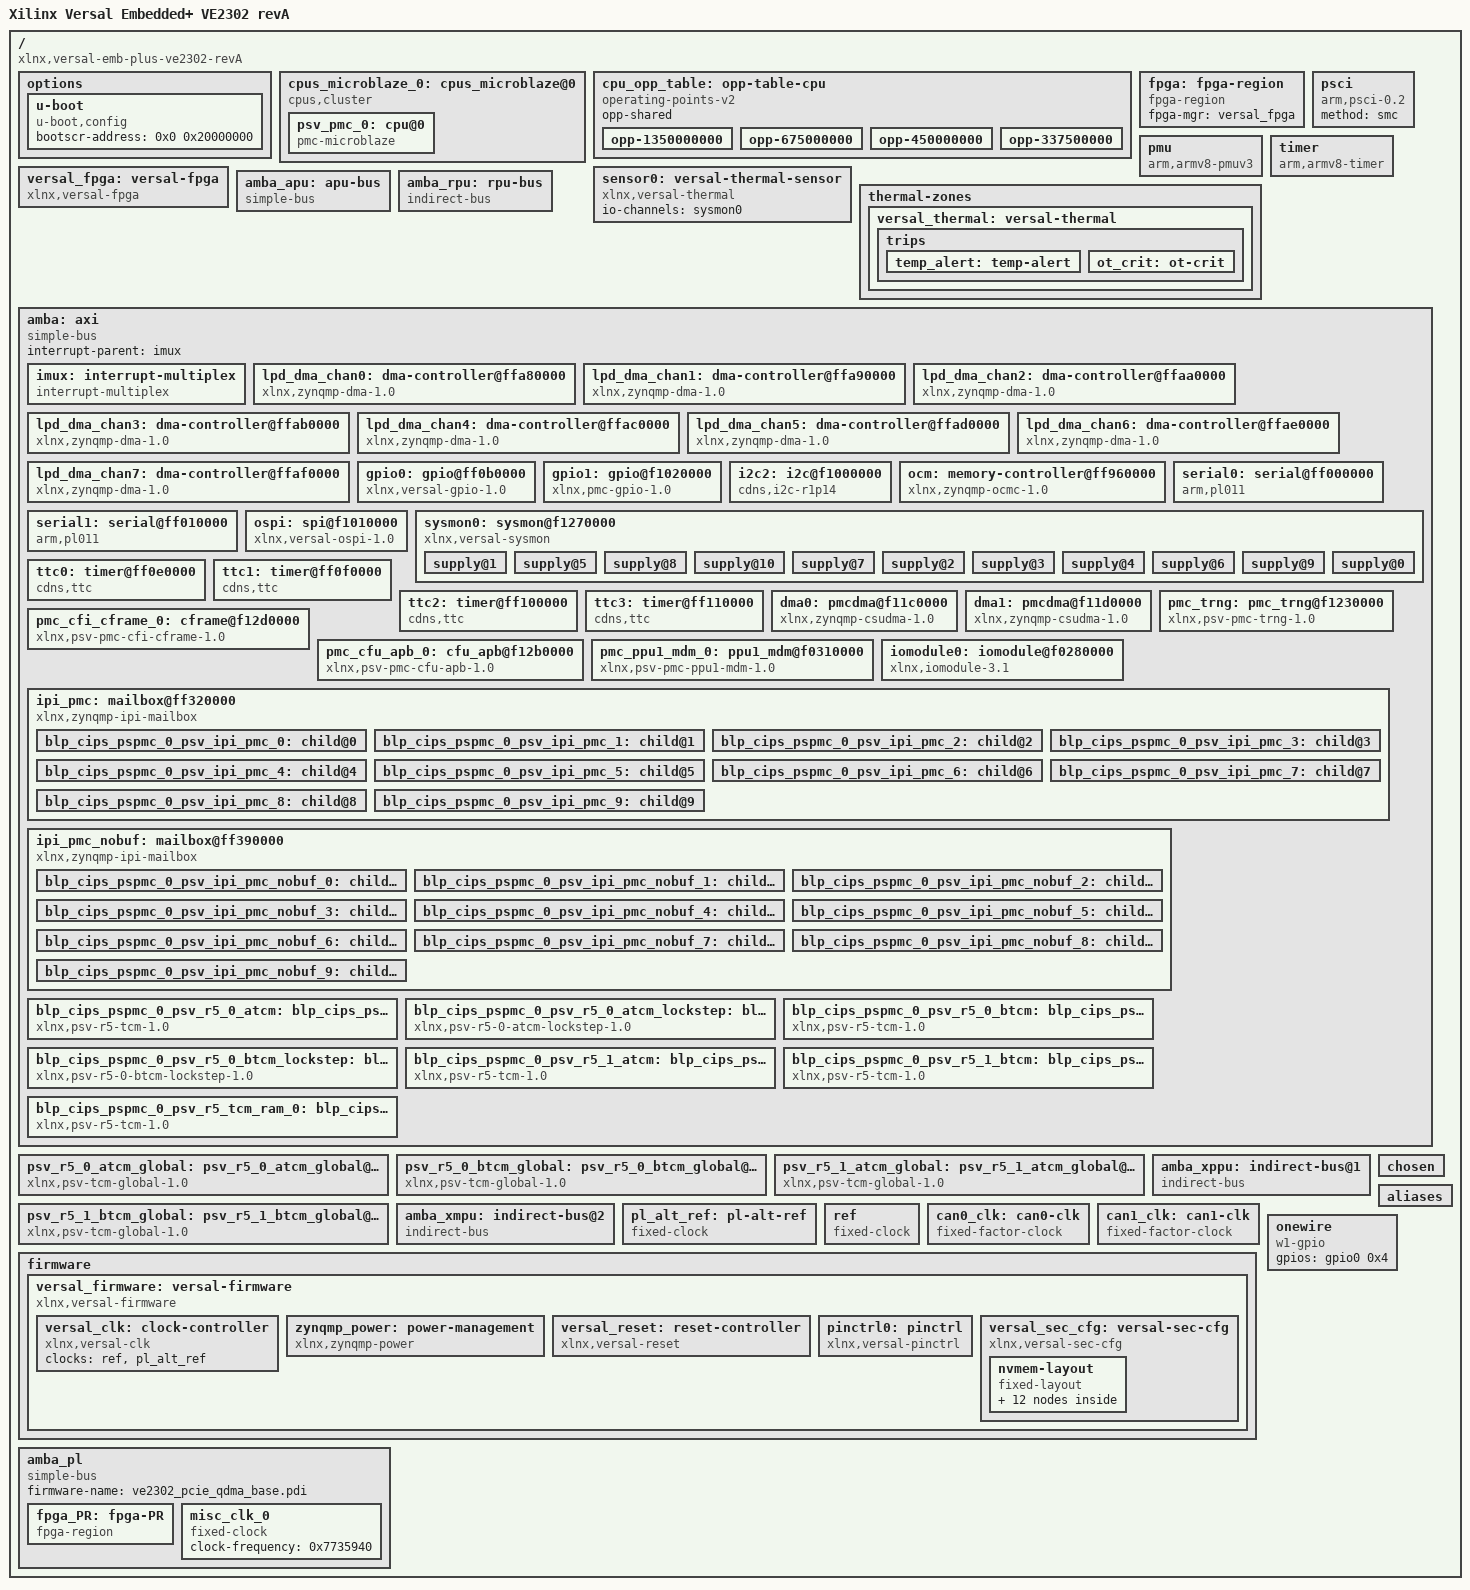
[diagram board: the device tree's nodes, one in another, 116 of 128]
/dts-v1/;
/ {
        compatible = "xlnx,versal-emb-plus-ve2302-revA", "xlnx,versal-emb-plus-ve2302", "xlnx,versal";
        #address-cells = <0x2>;
        #size-cells = <0x2>;
        model = "Xilinx Versal Embedded+ VE2302 revA";
        board = "emb-plus-vpr-4616";
        device_id = "xcve2302";
        slrcount = <0x1>;
        family = "Versal";
        speed_grade = "2MP";
        pruned-sdt = <0x1>;

        options {

                u-boot {
                        compatible = "u-boot,config";
                        bootscr-address = <0x0 0x20000000>;
                };
        };

        cpus_microblaze_0: cpus_microblaze@0 {
                #address-cells = <0x1>;
                #size-cells = <0x0>;
                compatible = "cpus,cluster";
                address-map = <0xf0000000 &amba 0xf0000000 0x10000000>,
                 <0xff320000 &ipi_pmc 0xff320000 0x10000>,
                 <0xff390000 &ipi_pmc_nobuf 0xff390000 0x10000>,
                 <0xf0310000 &pmc_ppu1_mdm_0 0xf0310000 0x8000>,
                 <0xf1000000 &i2c2 0xf1000000 0x10000>,
                 <0xf1010000 &ospi 0xf1010000 0x10000>,
                 <0xf1020000 &gpio1 0xf1020000 0x10000>,
                 <0xf11c0000 &dma0 0xf11c0000 0x10000>,
                 <0xf11d0000 &dma1 0xf11d0000 0x10000>,
                 <0xf1230000 &pmc_trng 0xf1230000 0x10000>,
                 <0xf1270000 &sysmon0 0xf1270000 0x30000>,
                 <0xf12b0000 &pmc_cfu_apb_0 0xf12b0000 0x10000>,
                 <0xf12d0000 &pmc_cfi_cframe_0 0xf12d0000 0x1000>,
                 <0xff000000 &serial0 0xff000000 0x10000>,
                 <0xff010000 &serial1 0xff010000 0x10000>,
                 <0xff0b0000 &gpio0 0xff0b0000 0x10000>,
                 <0xff0e0000 &ttc0 0xff0e0000 0x10000>,
                 <0xff0f0000 &ttc1 0xff0f0000 0x10000>,
                 <0xff100000 &ttc2 0xff100000 0x10000>,
                 <0xff110000 &ttc3 0xff110000 0x10000>,
                 <0xffa80000 &lpd_dma_chan0 0xffa80000 0x10000>,
                 <0xffa90000 &lpd_dma_chan1 0xffa90000 0x10000>,
                 <0xffaa0000 &lpd_dma_chan2 0xffaa0000 0x10000>,
                 <0xffab0000 &lpd_dma_chan3 0xffab0000 0x10000>,
                 <0xffac0000 &lpd_dma_chan4 0xffac0000 0x10000>,
                 <0xffad0000 &lpd_dma_chan5 0xffad0000 0x10000>,
                 <0xffae0000 &lpd_dma_chan6 0xffae0000 0x10000>,
                 <0xffaf0000 &lpd_dma_chan7 0xffaf0000 0x10000>,
                 <0xf0280000 &iomodule0 0xf0280000 0x1000>;
                #ranges-address-cells = <0x1>;
                #ranges-size-cells = <0x1>;
                phandle = <0xb6>;

                psv_pmc_0: cpu@0 {
                        compatible = "pmc-microblaze";
                        device_type = "cpu";
                        reg = <0x0>;
                        operating-points-v2 = <&cpu_opp_table>;
                        xlnx,d-axi = <0x1>;
                        xlnx,addr-tag-bits = <0x0>;
                        xlnx,m-axi-dc-thread-id-width = <0x1>;
                        xlnx,m0-axis-protocol = "GENERIC";
                        xlnx,dcache-force-tag-lutram = <0x0>;
                        xlnx,interrupt-is-edge = <0x0>;
                        xlnx,use-mmu = <0x0>;
                        xlnx,m-axi-dp-exclusive-access = <0x0>;
                        xlnx,use-reorder-instr = <0x1>;
                        xlnx,m14-axis-protocol = "GENERIC";
                        xlnx,use-div = <0x1>;
                        xlnx,dc-axi-mon = <0x0>;
                        xlnx,m-axi-ic-user-signals = <0x0>;
                        xlnx,use-config-reset = <0x0>;
                        xlnx,s14-axis-protocol = "GENERIC";
                        xlnx,mmu-zones = <0x10>;
                        xlnx,enable-discrete-ports = <0x0>;
                        xlnx,d-lmb = <0x1>;
                        xlnx,m-axi-dc-exclusive-access = <0x0>;
                        xlnx,debug-interface = <0x0>;
                        xlnx,s9-axis-protocol = "GENERIC";
                        xlnx,sco = <0x0>;
                        xlnx,use-ext-brk = <0x0>;
                        xlnx,debug-enabled = <0x1>;
                        xlnx,daddr-size = <0x20>;
                        xlnx,s0-axis-data-width = <0x20>;
                        xlnx,use-extended-fsl-instr = <0x0>;
                        xlnx,m-axi-dc-user-signals = <0x0>;
                        xlnx,reset-msr = <0x0>;
                        xlnx,branch-target-cache-size = <0x0>;
                        xlnx,s2-axis-data-width = <0x20>;
                        xlnx,cache-byte-size = <0x2000>;
                        bus-handle = <0x1>;
                        xlnx,mmu-tlb-access = <0x3>;
                        xlnx,s4-axis-data-width = <0x20>;
                        xlnx,m-axi-ic-awuser-width = <0x5>;
                        xlnx,s6-axis-data-width = <0x20>;
                        xlnx,s4-axis-protocol = "GENERIC";
                        xlnx,s8-axis-data-width = <0x20>;
                        xlnx,edk-special = "microblaze";
                        xlnx,use-dcache = <0x0>;
                        xlnx,m-axi-dp-addr-width = <0x20>;
                        xlnx,m-axi-ic-wuser-width = <0x1>;
                        xlnx,i-axi = <0x0>;
                        xlnx,icache-streams = <0x0>;
                        xlnx,m-axi-dc-awuser-width = <0x5>;
                        xlnx,pss-ref-clk-freq = <0x1fca034>;
                        xlnx,use-stack-protection = <0x1>;
                        xlnx,m6-axis-protocol = "GENERIC";
                        xlnx,num-sync-ff-dbg-clk = <0x1>;
                        xlnx,m-axi-ip-data-width = <0x20>;
                        d-cache-size = <0x2000>;
                        xlnx,use-pcmp-instr = <0x1>;
                        xlnx,area-optimized = <0x0>;
                        xlnx,avoid-primitives = <0x0>;
                        xlnx,m1-axis-protocol = "GENERIC";
                        xlnx,i-lmb = <0x1>;
                        xlnx,lockstep-select = <0x0>;
                        xlnx,dcache-data-width = <0x0>;
                        xlnx,icache-force-tag-lutram = <0x0>;
                        xlnx,m15-axis-protocol = "GENERIC";
                        xlnx,use-branch-target-cache = <0x0>;
                        xlnx,m-axi-ip-thread-id-width = <0x1>;
                        xlnx,mmu-itlb-size = <0x2>;
                        xlnx,number-of-pc-brk = <0x2>;
                        xlnx,imprecise-exceptions = <0x0>;
                        xlnx,m-axi-ic-buser-width = <0x1>;
                        xlnx,m-axi-ic-addr-width = <0x20>;
                        xlnx,s15-axis-protocol = "GENERIC";
                        d-cache-highaddr = <0x3fffffff>;
                        xlnx,m10-axis-protocol = "GENERIC";
                        xlnx,optimization = <0x0>;
                        xlnx,m-axi-ic-aruser-width = <0x5>;
                        xlnx,d-lmb-mon = <0x0>;
                        xlnx,s10-axis-protocol = "GENERIC";
                        xlnx,m-axi-ic-ruser-width = <0x1>;
                        xlnx,s5-axis-protocol = "GENERIC";
                        xlnx,fault-tolerant = <0x1>;
                        d-cache-line-size = <0x10>;
                        xlnx,m-axi-dc-aruser-width = <0x5>;
                        xlnx,mmu-privileged-instr = <0x0>;
                        xlnx,m-axi-i-bus-exception = <0x0>;
                        xlnx,reset-msr-eip = <0x0>;
                        xlnx,endianness = <0x1>;
                        xlnx,reset-msr-ice = <0x0>;
                        xlnx,dp-axi-mon = <0x0>;
                        xlnx,s10-axis-data-width = <0x20>;
                        xlnx,s0-axis-protocol = "GENERIC";
                        xlnx,s12-axis-data-width = <0x20>;
                        xlnx,m7-axis-protocol = "GENERIC";
                        xlnx,s14-axis-data-width = <0x20>;
                        xlnx,m-axi-d-bus-exception = <0x1>;
                        xlnx,reset-msr-bip = <0x1>;
                        xlnx,debug-external-trace = <0x0>;
                        xlnx,addr-size = <0x20>;
                        xlnx,m-axi-ic-user-value = <0x1f>;
                        xlnx,m1-axis-data-width = <0x20>;
                        xlnx,debug-event-counters = <0x5>;
                        xlnx,m3-axis-data-width = <0x20>;
                        xlnx,fpu-exception = <0x0>;
                        xlnx,m2-axis-protocol = "GENERIC";
                        xlnx,m5-axis-data-width = <0x20>;
                        xlnx,m7-axis-data-width = <0x20>;
                        xlnx,edk-iptype = "PROCESSOR";
                        xlnx,debug-latency-counters = <0x1>;
                        xlnx,interconnect = <0x2>;
                        xlnx,m9-axis-data-width = <0x20>;
                        xlnx,edge-is-positive = <0x1>;
                        xlnx,use-icache = <0x0>;
                        xlnx,async-wakeup = <0x3>;
                        xlnx,m10-axis-data-width = <0x20>;
                        xlnx,m12-axis-data-width = <0x20>;
                        xlnx,use-ext-nm-brk = <0x0>;
                        xlnx,m11-axis-protocol = "GENERIC";
                        xlnx,m14-axis-data-width = <0x20>;
                        xlnx,icache-always-used = <0x0>;
                        xlnx,ic-axi-mon = <0x0>;
                        xlnx,num-sync-ff-clk-irq = <0x1>;
                        xlnx,freq = <0x1312d000>;
                        xlnx,lockstep-master = <0x0>;
                        xlnx,s11-axis-protocol = "GENERIC";
                        xlnx,use-msr-instr = <0x1>;
                        xlnx,s6-axis-protocol = "GENERIC";
                        xlnx,iaddr-size = <0x20>;
                        xlnx,interrupt-mon = <0x0>;
                        xlnx,m-axi-dc-data-width = <0x20>;
                        xlnx,dynamic-bus-sizing = <0x0>;
                        xlnx,number-of-wr-addr-brk = <0x1>;
                        xlnx,use-interrupt = <0x1>;
                        xlnx,m-axi-ip-addr-width = <0x20>;
                        xlnx,async-interrupt = <0x1>;
                        xlnx,pc-width = <0x20>;
                        xlnx,icache-victims = <0x0>;
                        xlnx,reset-msr-ee = <0x0>;
                        xlnx,s1-axis-protocol = "GENERIC";
                        xlnx,m8-axis-protocol = "GENERIC";
                        i-cache-baseaddr = <0x0>;
                        xlnx,i-lmb-mon = <0x0>;
                        xlnx,dcache-byte-size = <0x2000>;
                        xlnx,m-axi-dp-thread-id-width = <0x1>;
                        xlnx,data-size = <0x20>;
                        xlnx,m-axi-dc-wuser-width = <0x1>;
                        xlnx,fsl-exception = <0x0>;
                        xlnx,m3-axis-protocol = "GENERIC";
                        xlnx,s1-axis-data-width = <0x20>;
                        xlnx,dcache-use-writeback = <0x0>;
                        xlnx,div-zero-exception = <0x1>;
                        xlnx,s3-axis-data-width = <0x20>;
                        xlnx,base-vectors = <0xf0240000>;
                        xlnx,icache-line-len = <0x4>;
                        xlnx,s5-axis-data-width = <0x20>;
                        xlnx,s7-axis-data-width = <0x20>;
                        xlnx,allow-dcache-wr = <0x1>;
                        xlnx,s9-axis-data-width = <0x20>;
                        xlnx,use-barrel = <0x1>;
                        xlnx,g-use-exceptions = <0x1>;
                        xlnx,dcache-line-len = <0x4>;
                        xlnx,m12-axis-protocol = "GENERIC";
                        xlnx,num-sync-ff-clk = <0x2>;
                        i-cache-size = <0x2000>;
                        xlnx,instance = "design_1_microblaze_0_0";
                        xlnx,reset-msr-ie = <0x0>;
                        xlnx,s12-axis-protocol = "GENERIC";
                        xlnx,dcache-addr-tag = <0x0>;
                        xlnx,m-axi-ic-thread-id-width = <0x1>;
                        xlnx,number-of-rd-addr-brk = <0x1>;
                        xlnx,m-axi-dc-buser-width = <0x1>;
                        xlnx,s7-axis-protocol = "GENERIC";
                        xlnx,lockstep-slave = <0x0>;
                        xlnx,debug-profile-size = <0x0>;
                        xlnx,s2-axis-protocol = "GENERIC";
                        xlnx,m9-axis-protocol = "GENERIC";
                        xlnx,debug-counter-width = <0x20>;
                        xlnx,icache-data-width = <0x0>;
                        xlnx,m-axi-dc-ruser-width = <0x1>;
                        xlnx,reset-msr-dce = <0x0>;
                        xlnx,ip-name = "psv_pmc";
                        xlnx,ip-axi-mon = <0x0>;
                        xlnx,m-axi-dp-data-width = <0x20>;
                        xlnx,m4-axis-protocol = "GENERIC";
                        xlnx,dcache-always-used = <0x0>;
                        xlnx,ill-opcode-exception = <0x1>;
                        xlnx,trace = <0x1>;
                        xlnx,pvr = <0x2>;
                        xlnx,debug-trace-size = <0x2000>;
                        i-cache-line-size = <0x10>;
                        xlnx,m13-axis-protocol = "GENERIC";
                        xlnx,s11-axis-data-width = <0x20>;
                        xlnx,m-axi-dc-addr-width = <0x20>;
                        xlnx,s13-axis-data-width = <0x20>;
                        xlnx,ecc-use-ce-exception = <0x0>;
                        xlnx,opcode-0x0-illegal = <0x1>;
                        xlnx,pvr-user2 = <0x0>;
                        xlnx,s15-axis-data-width = <0x20>;
                        xlnx,s13-axis-protocol = "GENERIC";
                        xlnx,m0-axis-data-width = <0x20>;
                        i-cache-highaddr = <0x3fffffff>;
                        xlnx,s8-axis-protocol = "GENERIC";
                        xlnx,m2-axis-data-width = <0x20>;
                        xlnx,num-sync-ff-clk-debug = <0x2>;
                        xlnx,allow-icache-wr = <0x1>;
                        xlnx,m4-axis-data-width = <0x20>;
                        xlnx,g-template-list = <0x0>;
                        xlnx,m6-axis-data-width = <0x20>;
                        xlnx,m-axi-ic-data-width = <0x20>;
                        xlnx,m8-axis-data-width = <0x20>;
                        xlnx,use-hw-mul = <0x2>;
                        xlnx,use-fpu = <0x0>;
                        xlnx,s3-axis-protocol = "GENERIC";
                        xlnx,use-non-secure = <0x0>;
                        d-cache-baseaddr = <0x0>;
                        xlnx,m11-axis-data-width = <0x20>;
                        xlnx,m13-axis-data-width = <0x20>;
                        xlnx,instr-size = <0x20>;
                        xlnx,m15-axis-data-width = <0x20>;
                        xlnx,mmu-dtlb-size = <0x4>;
                        xlnx,fsl-links = <0x0>;
                        xlnx,m5-axis-protocol = "GENERIC";
                        xlnx,dcache-victims = <0x0>;
                        xlnx,m-axi-dc-user-value = <0x1f>;
                        xlnx,unaligned-exceptions = <0x1>;
                        phandle = <0xb7>;
                };
        };

        cpu_opp_table: opp-table-cpu {
                compatible = "operating-points-v2";
                opp-shared;
                phandle = <0x8c>;

                opp-1350000000 {
                        opp-hz = <0x0 0x50775d80>;
                        clock-latency-ns = <0x7a120>;
                        opp-microvolt = <0xf4240>;
                };

                opp-675000000 {
                        opp-hz = <0x0 0x283baec0>;
                        clock-latency-ns = <0x7a120>;
                        opp-microvolt = <0xf4240>;
                };

                opp-450000000 {
                        opp-hz = <0x0 0x1ad27480>;
                        clock-latency-ns = <0x7a120>;
                        opp-microvolt = <0xf4240>;
                };

                opp-337500000 {
                        opp-hz = <0x0 0x141dd760>;
                        clock-latency-ns = <0x7a120>;
                        opp-microvolt = <0xf4240>;
                };
        };

        fpga: fpga-region {
                compatible = "fpga-region";
                fpga-mgr = <&versal_fpga>;
                #address-cells = <0x2>;
                #size-cells = <0x2>;
                phandle = <0xbf>;
        };

        psci: psci {
                compatible = "arm,psci-0.2";
                method = "smc";
                phandle = <0xc0>;
        };

        pmu {
                compatible = "arm,armv8-pmuv3";
                interrupt-parent = <&imux>;
                interrupts = <0x1 0x7 0x304>;
        };

        timer: timer {
                compatible = "arm,armv8-timer";
                interrupt-parent = <&imux>;
                interrupts = <0x1 0xd 0x4 0x1 0xe 0x4 0x1 0xb 0x4 0x1 0xa 0x4>;
                phandle = <0xc1>;
        };

        versal_fpga: versal-fpga {
                compatible = "xlnx,versal-fpga";
                phandle = <0xa8>;
        };

        sensor0: versal-thermal-sensor {
                compatible = "xlnx,versal-thermal";
                #thermal-sensor-cells = <0x0>;
                io-channels = <&sysmon0>;
                io-channel-names = "sysmon-temp-channel";
                phandle = <0xaa>;
        };

        thermal-zones {

                versal_thermal: versal-thermal {
                        polling-delay-passive = <0xfa>;
                        polling-delay = <0x3e8>;
                        thermal-sensors = <0xaa>;
                        phandle = <0xc2>;

                        trips {

                                temp_alert: temp-alert {
                                        temperature = <0x11170>;
                                        hysteresis = <0x0>;
                                        type = "passive";
                                        phandle = <0xc3>;
                                };

                                ot_crit: ot-crit {
                                        temperature = <0x1e848>;
                                        hysteresis = <0x0>;
                                        type = "critical";
                                        phandle = <0xc4>;
                                };
                        };
                };
        };

        amba_apu: apu-bus {
                compatible = "simple-bus";
                #address-cells = <0x2>;
                #size-cells = <0x2>;
                ranges;
                bootph-all;
                phandle = <0x2>;
        };

        amba_rpu: rpu-bus {
                compatible = "indirect-bus";
                #address-cells = <0x2>;
                #size-cells = <0x2>;
                ranges;
                bootph-all;
                phandle = <0x99>;
        };

        amba: axi {
                compatible = "simple-bus";
                #address-cells = <0x2>;
                #size-cells = <0x2>;
                ranges;
                interrupt-parent = <&imux>;
                bootph-all;
                phandle = <0x1>;

                imux: interrupt-multiplex {
                        compatible = "interrupt-multiplex";
                        #address-cells = <0x0>;
                        #interrupt-cells = <0x3>;
                        interrupt-controller;
                        interrupt-map-mask = <0x0 0xffff 0x0>;
                        interrupt-map = <0x0 0x14 0x0 0x4e 0x0 0x14 0x1 0x0 0x15 0x0 0x4e 0x0 0x15 0x1 0x0 0x6a 0x0 0x4e 0x0 0x6a 0x4 0x0 0x3c 0x0 0x4e 0x0 0x3c 0x4 0x0 0x3d 0x0 0x4e 0x0 0x3d 0x4 0x0 0x3e 0x0 0x4e 0x0 0x3e 0x4 0x0 0x3f 0x0 0x4e 0x0 0x3f 0x4 0x0 0x40 0x0 0x4e 0x0 0x40 0x4 0x0 0x41 0x0 0x4e 0x0 0x41 0x4 0x0 0x42 0x0 0x4e 0x0 0x42 0x4 0x0 0x43 0x0 0x4e 0x0 0x43 0x4 0x0 0x38 0x0 0x4e 0x0 0x38 0x4 0x0 0x3a 0x0 0x4e 0x0 0x3a 0x4 0x0 0xd 0x0 0x4e 0x0 0xd 0x4 0x0 0x7a 0x0 0x4e 0x0 0x7a 0x4 0x0 0xe 0x0 0x4e 0x0 0xe 0x4 0x0 0xf 0x0 0x4e 0x0 0xf 0x4 0x0 0x8e 0x0 0x4e 0x0 0x8e 0x4 0x0 0x8f 0x0 0x4e 0x0 0x8f 0x4 0x0 0x7e 0x0 0x4e 0x0 0x7e 0x4 0x0 0x80 0x0 0x4e 0x0 0x80 0x4 0x0 0x12 0x0 0x4e 0x0 0x12 0x4 0x0 0x13 0x0 0x4e 0x0 0x13 0x4 0x0 0x6b 0x0 0x4e 0x0 0x6b 0x4 0x0 0x7c 0x0 0x4e 0x0 0x7c 0x4 0x0 0x7d 0x0 0x4e 0x0 0x7d 0x4 0x0 0x10 0x0 0x4e 0x0 0x10 0x4 0x0 0x11 0x0 0x4e 0x0 0x11 0x4 0x0 0x16 0x0 0x4e 0x0 0x16 0x4 0x0 0x1a 0x0 0x4e 0x0 0x1a 0x4 0x0 0x4a 0x0 0x4e 0x0 0x4a 0x4 0x0 0x48 0x0 0x4e 0x0 0x48 0x4 0x0 0x1e 0x0 0x4e 0x0 0x1e 0x4 0x0 0x1f 0x0 0x4e 0x0 0x1f 0x4 0x0 0x83 0x0 0x4e 0x0 0x83 0x4 0x0 0x84 0x0 0x4e 0x0 0x84 0x4 0x0 0x14 0x0 0x9f 0x0 0x14 0x1 0x0 0x15 0x0 0x9f 0x0 0x15 0x1 0x0 0x6a 0x0 0x9f 0x0 0x6a 0x4 0x0 0x3c 0x0 0x9f 0x0 0x3c 0x4 0x0 0x3d 0x0 0x9f 0x0 0x3d 0x4 0x0 0x3e 0x0 0x9f 0x0 0x3e 0x4 0x0 0x3f 0x0 0x9f 0x0 0x3f 0x4 0x0 0x40 0x0 0x9f 0x0 0x40 0x4 0x0 0x41 0x0 0x9f 0x0 0x41 0x4 0x0 0x42 0x0 0x9f 0x0 0x42 0x4 0x0 0x43 0x0 0x9f 0x0 0x43 0x4 0x0 0x38 0x0 0x9f 0x0 0x38 0x4 0x0 0x3a 0x0 0x9f 0x0 0x3a 0x4 0x0 0xd 0x0 0x9f 0x0 0xd 0x4 0x0 0x7a 0x0 0x9f 0x0 0x7a 0x4 0x0 0xe 0x0 0x9f 0x0 0xe 0x4 0x0 0xf 0x0 0x9f 0x0 0xf 0x4 0x0 0x8e 0x0 0x9f 0x0 0x8e 0x4 0x0 0x8f 0x0 0x9f 0x0 0x8f 0x4 0x0 0x7e 0x0 0x9f 0x0 0x7e 0x4 0x0 0x80 0x0 0x9f 0x0 0x80 0x4 0x0 0x12 0x0 0x9f 0x0 0x12 0x4 0x0 0x13 0x0 0x9f 0x0 0x13 0x4 0x0 0x6b 0x0 0x9f 0x0 0x6b 0x4 0x0 0x7c 0x0 0x9f 0x0 0x7c 0x4 0x0 0x7d 0x0 0x9f 0x0 0x7d 0x4 0x0 0x10 0x0 0x9f 0x0 0x10 0x4 0x0 0x11 0x0 0x9f 0x0 0x11 0x4 0x0 0x16 0x0 0x9f 0x0 0x16 0x4 0x0 0x1a 0x0 0x9f 0x0 0x1a 0x4 0x0 0x4a 0x0 0x9f 0x0 0x4a 0x4 0x0 0x48 0x0 0x9f 0x0 0x48 0x4 0x0 0x1e 0x0 0x9f 0x0 0x1e 0x4 0x0 0x1f 0x0 0x9f 0x0 0x1f 0x4 0x0 0x83 0x0 0x9f 0x0 0x83 0x4 0x0 0x84 0x0 0x9f 0x0 0x84 0x4>;
                        phandle = <0xa9>;
                };

                lpd_dma_chan0: dma-controller@ffa80000 {
                        compatible = "xlnx,zynqmp-dma-1.0";
                        status = "okay";
                        reg = <0x0 0xffa80000 0x0 0x1000>;
                        interrupts = <0x0 0x3c 0x4>;
                        interrupt-parent = <&imux>;
                        clock-names = "clk_main", "clk_apb";
                        xlnx,dma-type = <0x1>;
                        #dma-cells = <0x1>;
                        xlnx,bus-width = <0x40>;
                        clocks = <&versal_clk 0x51>,
                         <&versal_clk 0x52>;
                        power-domains = <&versal_firmware 0x18224035>;
                        xlnx,is-cache-coherent = <0x0>;
                        xlnx,ip-name = "psv_adma";
                        xlnx,dma-mode = <0x1>;
                        xlnx,name = "blp_cips_pspmc_0_psv_adma_0";
                        phandle = <0x7b>;
                };

                lpd_dma_chan1: dma-controller@ffa90000 {
                        compatible = "xlnx,zynqmp-dma-1.0";
                        status = "okay";
                        reg = <0x0 0xffa90000 0x0 0x1000>;
                        interrupts = <0x0 0x3d 0x4>;
                        interrupt-parent = <&imux>;
                        clock-names = "clk_main", "clk_apb";
                        xlnx,dma-type = <0x1>;
                        #dma-cells = <0x1>;
                        xlnx,bus-width = <0x40>;
                        clocks = <&versal_clk 0x51>,
                         <&versal_clk 0x52>;
                        power-domains = <&versal_firmware 0x18224036>;
                        xlnx,is-cache-coherent = <0x0>;
                        xlnx,ip-name = "psv_adma";
                        xlnx,dma-mode = <0x1>;
                        xlnx,name = "blp_cips_pspmc_0_psv_adma_1";
                        phandle = <0x7c>;
                };

                lpd_dma_chan2: dma-controller@ffaa0000 {
                        compatible = "xlnx,zynqmp-dma-1.0";
                        status = "okay";
                        reg = <0x0 0xffaa0000 0x0 0x1000>;
                        interrupts = <0x0 0x3e 0x4>;
                        interrupt-parent = <&imux>;
                        clock-names = "clk_main", "clk_apb";
                        xlnx,dma-type = <0x1>;
                        #dma-cells = <0x1>;
                        xlnx,bus-width = <0x40>;
                        clocks = <&versal_clk 0x51>,
                         <&versal_clk 0x52>;
                        power-domains = <&versal_firmware 0x18224037>;
                        xlnx,is-cache-coherent = <0x0>;
                        xlnx,ip-name = "psv_adma";
                        xlnx,dma-mode = <0x1>;
                        xlnx,name = "blp_cips_pspmc_0_psv_adma_2";
                        phandle = <0x7d>;
                };

                lpd_dma_chan3: dma-controller@ffab0000 {
                        compatible = "xlnx,zynqmp-dma-1.0";
                        status = "okay";
                        reg = <0x0 0xffab0000 0x0 0x1000>;
                        interrupts = <0x0 0x3f 0x4>;
                        interrupt-parent = <&imux>;
                        clock-names = "clk_main", "clk_apb";
                        xlnx,dma-type = <0x1>;
                        #dma-cells = <0x1>;
                        xlnx,bus-width = <0x40>;
                        clocks = <&versal_clk 0x51>,
                         <&versal_clk 0x52>;
                        power-domains = <&versal_firmware 0x18224038>;
                        xlnx,is-cache-coherent = <0x0>;
                        xlnx,ip-name = "psv_adma";
                        xlnx,dma-mode = <0x1>;
                        xlnx,name = "blp_cips_pspmc_0_psv_adma_3";
                        phandle = <0x7e>;
                };

                lpd_dma_chan4: dma-controller@ffac0000 {
                        compatible = "xlnx,zynqmp-dma-1.0";
                        status = "okay";
                        reg = <0x0 0xffac0000 0x0 0x1000>;
                        interrupts = <0x0 0x40 0x4>;
                        interrupt-parent = <&imux>;
                        clock-names = "clk_main", "clk_apb";
                        xlnx,dma-type = <0x1>;
                        #dma-cells = <0x1>;
                        xlnx,bus-width = <0x40>;
                        clocks = <&versal_clk 0x51>,
                         <&versal_clk 0x52>;
                        power-domains = <&versal_firmware 0x18224039>;
                        xlnx,is-cache-coherent = <0x0>;
                        xlnx,ip-name = "psv_adma";
                        xlnx,dma-mode = <0x1>;
                        xlnx,name = "blp_cips_pspmc_0_psv_adma_4";
                        phandle = <0x7f>;
                };

                lpd_dma_chan5: dma-controller@ffad0000 {
                        compatible = "xlnx,zynqmp-dma-1.0";
                        status = "okay";
                        reg = <0x0 0xffad0000 0x0 0x1000>;
                        interrupts = <0x0 0x41 0x4>;
                        interrupt-parent = <&imux>;
                        clock-names = "clk_main", "clk_apb";
                        xlnx,dma-type = <0x1>;
                        #dma-cells = <0x1>;
                        xlnx,bus-width = <0x40>;
                        clocks = <&versal_clk 0x51>,
                         <&versal_clk 0x52>;
                        power-domains = <&versal_firmware 0x1822403a>;
                        xlnx,is-cache-coherent = <0x0>;
                        xlnx,ip-name = "psv_adma";
                        xlnx,dma-mode = <0x1>;
                        xlnx,name = "blp_cips_pspmc_0_psv_adma_5";
                        phandle = <0x80>;
                };

                lpd_dma_chan6: dma-controller@ffae0000 {
                        compatible = "xlnx,zynqmp-dma-1.0";
                        status = "okay";
                        reg = <0x0 0xffae0000 0x0 0x1000>;
                        interrupts = <0x0 0x42 0x4>;
                        interrupt-parent = <&imux>;
                        clock-names = "clk_main", "clk_apb";
                        xlnx,dma-type = <0x1>;
                        #dma-cells = <0x1>;
                        xlnx,bus-width = <0x40>;
                        clocks = <&versal_clk 0x51>,
                         <&versal_clk 0x52>;
                        power-domains = <&versal_firmware 0x1822403b>;
                        xlnx,is-cache-coherent = <0x0>;
                        xlnx,ip-name = "psv_adma";
                        xlnx,dma-mode = <0x1>;
                        xlnx,name = "blp_cips_pspmc_0_psv_adma_6";
                        phandle = <0x81>;
                };

                lpd_dma_chan7: dma-controller@ffaf0000 {
                        compatible = "xlnx,zynqmp-dma-1.0";
                        status = "okay";
                        reg = <0x0 0xffaf0000 0x0 0x1000>;
                        interrupts = <0x0 0x43 0x4>;
                        interrupt-parent = <&imux>;
                        clock-names = "clk_main", "clk_apb";
                        xlnx,dma-type = <0x1>;
                        #dma-cells = <0x1>;
                        xlnx,bus-width = <0x40>;
                        clocks = <&versal_clk 0x51>,
                         <&versal_clk 0x52>;
                        power-domains = <&versal_firmware 0x1822403c>;
                        xlnx,is-cache-coherent = <0x0>;
                        xlnx,ip-name = "psv_adma";
                        xlnx,dma-mode = <0x1>;
                        xlnx,name = "blp_cips_pspmc_0_psv_adma_7";
                        phandle = <0x82>;
                };

                gpio0: gpio@ff0b0000 {
                        compatible = "xlnx,versal-gpio-1.0";
                        status = "okay";
                        reg = <0x0 0xff0b0000 0x0 0x1000>;
                        interrupts = <0x0 0xd 0x4>;
                        interrupt-parent = <&imux>;
                        #gpio-cells = <0x2>;
                        gpio-controller;
                        #interrupt-cells = <0x2>;
                        interrupt-controller;
                        clocks = <&versal_clk 0x52>;
                        power-domains = <&versal_firmware 0x18224023>;
                        xlnx,ip-name = "psv_gpio";
                        emio-gpio-width = "";
                        xlnx,name = "blp_cips_pspmc_0_psv_gpio_2";
                        gpio-line-names = [47 50 49 4F 5F 4C 45 44 32 00 47 50 49 4F 5F 4C 45 44 33 00 47 50 49 4F 5F 4C 45 44 34 00 00 31 57 49 52 45 00 00 46 55 53 41 00 00 45 47 50 49 4F 00 41 47 50 49 4F 00 49 32 43 30 5F 53 43 4C 00 49 32 43 30 5F 53 44 41 00 00 00 00 00 00 00 00 00 00 00 00 00 33 56 33 5F 4D 4F 4E 5F 4E 00 33 56 33 5F 4D 4F 4E 5F 50 00 00 00 00 00 00 00 00 00 00 00 00 00 00 00 00 00 00 00 00 00 00 00 00 00 00 00 00 00 00 00 00];
                        phandle = <0x61>;
                };

                gpio1: gpio@f1020000 {
                        compatible = "xlnx,pmc-gpio-1.0";
                        status = "okay";
                        reg = <0x0 0xf1020000 0x0 0x1000>;
                        interrupts = <0x0 0x7a 0x4>;
                        interrupt-parent = <&imux>;
                        #gpio-cells = <0x2>;
                        gpio-controller;
                        #interrupt-cells = <0x2>;
                        interrupt-controller;
                        clocks = <&versal_clk 0x3d>;
                        power-domains = <&versal_firmware 0x1822402c>;
                        xlnx,ip-name = "psv_pmc_gpio";
                        xlnx,name = "blp_cips_pspmc_0_psv_pmc_gpio_0";
                        phandle = <0x36>;
                };

                i2c2: i2c@f1000000 {
                        compatible = "cdns,i2c-r1p14";
                        status = "okay";
                        reg = <0x0 0xf1000000 0x0 0x1000>;
                        interrupts = <0x0 0x7b 0x4>;
                        interrupt-parent = <&imux>;
                        clock-frequency = <0x186a0>;
                        #address-cells = <0x1>;
                        #size-cells = <0x0>;
                        clocks = <&versal_clk 0x3e>;
                        power-domains = <&versal_firmware 0x1822402d>;
                        xlnx,clock-freq = <0x5f5e09d>;
                        xlnx,i2c-clk-freq-hz = <0x5f5e09d>;
                        xlnx,ip-name = "psv_pmc_i2c";
                        xlnx,name = "blp_cips_pspmc_0_psv_pmc_i2c_0";
                        phandle = <0x34>;
                };

                ocm: memory-controller@ff960000 {
                        compatible = "xlnx,zynqmp-ocmc-1.0";
                        reg = <0x0 0xff960000 0x0 0x1000>;
                        interrupts = <0x0 0xa 0x4>;
                        interrupt-parent = <&imux>;
                        phandle = <0xd0>;
                };

                serial0: serial@ff000000 {
                        compatible = "arm,pl011", "arm,primecell";
                        status = "okay";
                        reg = <0x0 0xff000000 0x0 0x1000>;
                        interrupts = <0x0 0x12 0x4>;
                        interrupt-parent = <&imux>;
                        reg-io-width = <0x4>;
                        clock-names = "uartclk", "apb_pclk";
                        bootph-all;
                        clocks = <&versal_clk 0x5c>,
                         <&versal_clk 0x52>;
                        power-domains = <&versal_firmware 0x18224021>;
                        xlnx,clock-freq = <0x5f5e0a4>;
                        u-boot,dm-pre-reloc;
                        xlnx,uart-board-interface = "custom";
                        xlnx,has-modem = <0x0>;
                        xlnx,ip-name = "psv_sbsauart";
                        xlnx,baudrate = <0x1c200>;
                        cts-override;
                        port-number = <0x0>;
                        xlnx,uart-clk-freq-hz = <0x5f5e0a4>;
                        xlnx,name = "blp_cips_pspmc_0_psv_sbsauart_0";
                        phandle = <0x5c>;
                };

                serial1: serial@ff010000 {
                        compatible = "arm,pl011", "arm,primecell";
                        status = "okay";
                        reg = <0x0 0xff010000 0x0 0x1000>;
                        interrupts = <0x0 0x13 0x4>;
                        interrupt-parent = <&imux>;
                        reg-io-width = <0x4>;
                        clock-names = "uartclk", "apb_pclk";
                        bootph-all;
                        clocks = <&versal_clk 0x5d>,
                         <&versal_clk 0x52>;
                        power-domains = <&versal_firmware 0x18224022>;
                        xlnx,clock-freq = <0x5f5e0a4>;
                        u-boot,dm-pre-reloc;
                        xlnx,uart-board-interface = "custom";
                        xlnx,has-modem = <0x0>;
                        xlnx,ip-name = "psv_sbsauart";
                        xlnx,baudrate = <0x1c200>;
                        cts-override;
                        port-number = <0x0>;
                        xlnx,uart-clk-freq-hz = <0x5f5e0a4>;
                        xlnx,name = "blp_cips_pspmc_0_psv_sbsauart_1";
                        phandle = <0x5d>;
                };

                ospi: spi@f1010000 {
                        compatible = "xlnx,versal-ospi-1.0", "cdns,qspi-nor";
                        status = "okay";
                        reg = <0x0 0xf1010000 0x0 0x10000 0x0 0xc0000000 0x0 0x20000000>;
                        interrupts = <0x0 0x7c 0x4>;
                        interrupt-parent = <&imux>;
                        cdns,fifo-depth = <0x100>;
                        cdns,fifo-width = <0x4>;
                        cdns,is-dma = <0x1>;
                        cdns,trigger-address = <0xc0000000>;
                        #address-cells = <0x1>;
                        #size-cells = <0x0>;
                        clocks = <&versal_clk 0x3a>;
                        power-domains = <&versal_firmware 0x1822402a>;
                        reset-names = "qspi";
                        resets = <&versal_reset 0xc10402e>;
                        is-stacked = <0x0>;
                        xlnx,is-cache-coherent = <0x0>;
                        xlnx,clock-freq = <0x9cacc71>;
                        xlnx,ip-name = "psv_pmc_ospi";
                        xlnx,ospi-clk-freq-hz = <0x9cacc71>;
                        is-dual = <0x0>;
                        xlnx,ospi-mode = <0x0>;
                        xlnx,name = "blp_cips_pspmc_0_psv_pmc_ospi_0";
                        phandle = <0x35>;
                };

                sysmon0: sysmon@f1270000 {
                        compatible = "xlnx,versal-sysmon";
                        #io-channel-cells = <0x0>;
                        reg = <0x0 0xf1270000 0x0 0x4000>;
                        interrupts = <0x0 0x90 0x4>;
                        xlnx,numchannels = [0B];
                        #address-cells = <0x2>;
                        #size-cells = <0x2>;
                        xlnx,nodeid = <0x18224055>;
                        xlnx,sat-63-desc = "PS , FPD , satellite";
                        xlnx,sat-1-desc = "PMC , system , ADC";
                        xlnx,sat-9-x = <0xae2>;
                        xlnx,sat-9-y = <0x2905>;
                        xlnx,meas-0-root-id = <0x1>;
                        xlnx,meas-7-slr-number = <0x0>;
                        xlnx,meas-10-root-id = <0x0>;
                        xlnx,ip-name = "psv_pmc_sysmon";
                        xlnx,meas-1-root-id = <0x5>;
                        xlnx,meas-2-root-id = <0x8>;
                        xlnx,meas-2-slr-number = <0x0>;
                        xlnx,meas-3-root-id = <0xa>;
                        xlnx,sat-9-desc = "ME , satellite";
                        xlnx,meas-4-root-id = <0x7>;
                        xlnx,meas-5-root-id = <0x2>;
                        xlnx,sat-10-x = <0x319>;
                        xlnx,sat-64-x = <0x23>;
                        xlnx,sat-2-x = <0x23>;
                        xlnx,meas-6-root-id = <0x3>;
                        xlnx,sat-10-y = <0x2905>;
                        xlnx,sat-64-y = <0xb34>;
                        xlnx,sat-2-y = <0xb34>;
                        xlnx,meas-7-root-id = <0x4>;
                        xlnx,sat-13-desc = "Clocking , column , satellite";
                        xlnx,meas-8-root-id = <0x6>;
                        xlnx,sat-6-desc = "VNOC , satellite";
                        xlnx,meas-9-root-id = <0x9>;
                        xlnx,sat-6-x = <0x1a37>;
                        xlnx,sat-6-y = <0x19f9>;
                        xlnx,sat-10-desc = "ME , satellite";
                        xlnx,sat-3-desc = "XPIO , satellite";
                        xlnx,meas-5-slr-number = <0x0>;
                        xlnx,meas-10-aux-io-n = "LPD_MIO25_502";
                        xlnx,meas-0-slr-number = <0x0>;
                        xlnx,meas-10-aux-io-p = "LPD_MIO24_502";
                        xlnx,sat-11-x = <0xa0e>;
                        xlnx,sat-3-x = <0x116a>;
                        xlnx,sat-11-y = <0x23fc>;
                        xlnx,sat-3-y = <0x5ff>;
                        status = "okay";
                        xlnx,meas-8-slr-number = <0x0>;
                        xlnx,sat-8-desc = "ME , satellite";
                        xlnx,sat-7-x = <0x1a74>;
                        xlnx,name = "blp_cips_pspmc_0_psv_pmc_sysmon_0";
                        xlnx,sat-7-y = <0x2905>;
                        xlnx,meas-3-slr-number = <0x0>;
                        xlnx,sat-12-desc = "Clocking , column , satellite";
                        xlnx,sat-5-desc = "VNOC , satellite";
                        xlnx,sat-64-desc = "PS , LPD , satellite";
                        xlnx,sat-2-desc = "PMC , user , ADC";
                        xlnx,meas-6-slr-number = <0x0>;
                        xlnx,sat-12-x = <0xa0e>;
                        xlnx,sat-4-x = <0x1d4c>;
                        xlnx,sat-12-y = <0x1dc4>;
                        xlnx,sat-4-y = <0x5ff>;
                        xlnx,meas-10-slr-number = <0x0>;
                        xlnx,meas-1-slr-number = <0x0>;
                        xlnx,sat-8-x = <0x12ab>;
                        xlnx,sat-8-y = <0x2905>;
                        xlnx,meas-0 = "VCCAUX";
                        xlnx,meas-10 = "VAUX_CH0";
                        xlnx,meas-1 = "VCC_SOC";
                        xlnx,meas-2 = "VCCO_302";
                        xlnx,meas-3 = "VCCAUX_PMC";
                        xlnx,meas-4 = "VCCO_500";
                        xlnx,sat-7-desc = "ME , satellite";
                        xlnx,meas-5 = "VCC_PMC";
                        xlnx,meas-9-slr-number = <0x0>;
                        xlnx,meas-6 = "VCC_PSFP";
                        xlnx,meas-7 = "VCC_PSLP";
                        xlnx,sat-63-x = <0x23>;
                        xlnx,sat-1-x = <0x23>;
                        xlnx,meas-4-slr-number = <0x0>;
                        xlnx,meas-8 = "VP_VN";
                        xlnx,sat-11-desc = "Clocking , column , satellite";
                        xlnx,sat-63-y = <0xb34>;
                        xlnx,sat-1-y = <0xb34>;
                        xlnx,meas-9 = "VCCO_703";
                        xlnx,sat-4-desc = "XPIO , satellite";
                        xlnx,sat-13-x = <0xa0e>;
                        xlnx,sat-5-x = <0x1a37>;
                        xlnx,sat-13-y = <0x1795>;
                        xlnx,sat-5-y = <0xe06>;
                        phandle = <0x45>;

                        supply@1 {
                                reg = <0x1>;
                                xlnx,name = "vccaux";
                        };

                        supply@5 {
                                reg = <0x5>;
                                xlnx,name = "vcc_soc";
                        };

                        supply@8 {
                                reg = <0x8>;
                                xlnx,name = "vcco_302";
                        };

                        supply@10 {
                                reg = <0xa>;
                                xlnx,name = "vccaux_pmc";
                        };

                        supply@7 {
                                reg = <0x7>;
                                xlnx,name = "vcco_500";
                        };

                        supply@2 {
                                reg = <0x2>;
                                xlnx,name = "vcc_pmc";
                        };

                        supply@3 {
                                reg = <0x3>;
                                xlnx,name = "vcc_psfp";
                        };

                        supply@4 {
                                reg = <0x4>;
                                xlnx,name = "vcc_pslp";
                        };

                        supply@6 {
                                reg = <0x6>;
                                xlnx,name = "vp_vn";
                        };

                        supply@9 {
                                reg = <0x9>;
                                xlnx,name = "vcco_703";
                        };

                        supply@0 {
                                reg = <0x0>;
                                xlnx,name = "vaux_ch0";
                        };
                };

                ttc0: timer@ff0e0000 {
                        compatible = "cdns,ttc";
                        status = "okay";
                        interrupts = <0x0 0x25 0x4 0x0 0x26 0x4 0x0 0x27 0x4>;
                        interrupt-parent = <&imux>;
                        reg = <0x0 0xff0e0000 0x0 0x1000>;
                        timer-width = <0x20>;
                        clocks = <&versal_clk 0x27>;
                        power-domains = <&versal_firmware 0x18224024>;
                        xlnx,ttc-board-interface = "custom";
                        xlnx,ttc-clk2-freq-hz = <0x8ab7547>;
                        xlnx,ttc-clk1-clksrc = <0x0>;
                        xlnx,clock-freq = <0x8ab7547>;
                        xlnx,ttc-clk2-clksrc = <0x0>;
                        xlnx,ip-name = "psv_ttc";
                        xlnx,ttc-clk0-freq-hz = <0x8ab7547>;
                        xlnx,ttc-clk1-freq-hz = <0x8ab7547>;
                        xlnx,ttc-clk0-clksrc = <0x0>;
                        xlnx,name = "blp_cips_pspmc_0_psv_ttc_0";
                        phandle = <0x62>;
                };

                ttc1: timer@ff0f0000 {
                        compatible = "cdns,ttc";
                        status = "okay";
                        interrupts = <0x0 0x28 0x4 0x0 0x29 0x4 0x0 0x2a 0x4>;
                        interrupt-parent = <&imux>;
                        reg = <0x0 0xff0f0000 0x0 0x1000>;
                        timer-width = <0x20>;
                        clocks = <&versal_clk 0x28>;
                        power-domains = <&versal_firmware 0x18224025>;
                        xlnx,ttc-board-interface = "custom";
                        xlnx,ttc-clk2-freq-hz = <0x8ab7547>;
                        xlnx,ttc-clk1-clksrc = <0x0>;
                        xlnx,clock-freq = <0x8ab7547>;
                        xlnx,ttc-clk2-clksrc = <0x0>;
                        xlnx,ip-name = "psv_ttc";
                        xlnx,ttc-clk0-freq-hz = <0x8ab7547>;
                        xlnx,ttc-clk1-freq-hz = <0x8ab7547>;
                        xlnx,ttc-clk0-clksrc = <0x0>;
                        xlnx,name = "blp_cips_pspmc_0_psv_ttc_1";
                        phandle = <0x63>;
                };

                ttc2: timer@ff100000 {
                        compatible = "cdns,ttc";
                        status = "okay";
                        interrupts = <0x0 0x2b 0x4 0x0 0x2c 0x4 0x0 0x2d 0x4>;
                        interrupt-parent = <&imux>;
                        reg = <0x0 0xff100000 0x0 0x1000>;
                        timer-width = <0x20>;
                        clocks = <&versal_clk 0x29>;
                        power-domains = <&versal_firmware 0x18224026>;
                        xlnx,ttc-board-interface = "custom";
                        xlnx,ttc-clk2-freq-hz = <0x8ab7547>;
                        xlnx,ttc-clk1-clksrc = <0x0>;
                        xlnx,clock-freq = <0x8ab7547>;
                        xlnx,ttc-clk2-clksrc = <0x0>;
                        xlnx,ip-name = "psv_ttc";
                        xlnx,ttc-clk0-freq-hz = <0x8ab7547>;
                        xlnx,ttc-clk1-freq-hz = <0x8ab7547>;
                        xlnx,ttc-clk0-clksrc = <0x0>;
                        xlnx,name = "blp_cips_pspmc_0_psv_ttc_2";
                        phandle = <0x64>;
                };

                ttc3: timer@ff110000 {
                        compatible = "cdns,ttc";
                        status = "okay";
                        interrupts = <0x0 0x2e 0x4 0x0 0x2f 0x4 0x0 0x30 0x4>;
                        interrupt-parent = <&imux>;
                        reg = <0x0 0xff110000 0x0 0x1000>;
                        timer-width = <0x20>;
                        clocks = <&versal_clk 0x2a>;
                        power-domains = <&versal_firmware 0x18224027>;
                        xlnx,ttc-board-interface = "custom";
                        xlnx,ttc-clk2-freq-hz = <0x8ab7547>;
                        xlnx,ttc-clk1-clksrc = <0x0>;
                        xlnx,clock-freq = <0x8ab7547>;
                        xlnx,ttc-clk2-clksrc = <0x0>;
                        xlnx,ip-name = "psv_ttc";
                        xlnx,ttc-clk0-freq-hz = <0x8ab7547>;
                        xlnx,ttc-clk1-freq-hz = <0x8ab7547>;
                        xlnx,ttc-clk0-clksrc = <0x0>;
                        xlnx,name = "blp_cips_pspmc_0_psv_ttc_3";
                        phandle = <0x65>;
                };

                dma0: pmcdma@f11c0000 {
                        status = "okay";
                        compatible = "xlnx,zynqmp-csudma-1.0";
                        interrupt-parent = <&imux>;
                        interrupts = <0x0 0x83 0x4>;
                        reg = <0x0 0xf11c0000 0x0 0x10000>;
                        xlnx,dma-type = <0x1>;
                        xlnx,ip-name = "psv_pmc_dma";
                        xlnx,name = "blp_cips_pspmc_0_psv_pmc_dma_0";
                        phandle = <0x3a>;
                };

                dma1: pmcdma@f11d0000 {
                        status = "okay";
                        compatible = "xlnx,zynqmp-csudma-1.0";
                        interrupt-parent = <&imux>;
                        interrupts = <0x0 0x84 0x4>;
                        reg = <0x0 0xf11d0000 0x0 0x10000>;
                        xlnx,dma-type = <0x2>;
                        xlnx,ip-name = "psv_pmc_dma";
                        xlnx,name = "blp_cips_pspmc_0_psv_pmc_dma_1";
                        phandle = <0x3b>;
                };

                pmc_trng: pmc_trng@f1230000 {
                        compatible = "xlnx,psv-pmc-trng-1.0";
                        status = "okay";
                        reg = <0x0 0xf1230000 0x0 0x10000>;
                        xlnx,device-id = <0x0>;
                        xlnx,ip-name = "psv_pmc_trng";
                        xlnx,name = "blp_cips_pspmc_0_psv_pmc_trng";
                        phandle = <0x41>;
                };

                pmc_cfi_cframe_0: cframe@f12d0000 {
                        compatible = "xlnx,psv-pmc-cfi-cframe-1.0";
                        status = "okay";
                        reg = <0x0 0xf12d0000 0x0 0x1000>;
                        xlnx,ip-name = "psv_pmc_cfi_cframe";
                        xlnx,name = "blp_cips_pspmc_0_psv_pmc_cfi_cframe_0";
                        phandle = <0x48>;
                };

                pmc_cfu_apb_0: cfu_apb@f12b0000 {
                        compatible = "xlnx,psv-pmc-cfu-apb-1.0";
                        status = "okay";
                        reg = <0x0 0xf12b0000 0x0 0x10000>;
                        xlnx,ip-name = "psv_pmc_cfu_apb";
                        xlnx,name = "blp_cips_pspmc_0_psv_pmc_cfu_apb_0";
                        phandle = <0x47>;
                };

                pmc_ppu1_mdm_0: ppu1_mdm@f0310000 {
                        compatible = "xlnx,psv-pmc-ppu1-mdm-1.0";
                        status = "okay";
                        reg = <0x0 0xf0310000 0x0 0x8000>;
                        xlnx,ip-name = "psv_pmc_ppu1_mdm";
                        xlnx,name = "blp_cips_pspmc_0_psv_pmc_ppu1_mdm_0";
                        phandle = <0x13>;
                };

                iomodule0: iomodule@f0280000 {
                        status = "okay";
                        compatible = "xlnx,iomodule-3.1";
                        reg = <0x0 0xf0280000 0x0 0x1000 0xffffffff 0xffffffff 0x0 0xe0000>;
                        xlnx,intc-has-fast = <0x0>;
                        xlnx,intc-base-vectors = <0xf0240000>;
                        xlnx,intc-addr-width = <0x20>;
                        xlnx,intc-level-edge = <0x7fff>;
                        xlnx,clock-freq = <0x5f5e100>;
                        xlnx,uart-baudrate = <0x1c200>;
                        xlnx,pit-used = <0x1 0x1 0x1 0x1>;
                        xlnx,pit-size = <0x20 0x20 0x20 0x20>;
                        xlnx,pit-mask = <0xffffffff 0xffffffff 0xffffffff 0xffffffff>;
                        xlnx,pit-prescaler = <0x9 0x0 0x9 0x0>;
                        xlnx,pit-readable = <0x1 0x1 0x1 0x1>;
                        xlnx,gpo-init = <0x0 0x0 0x0 0x0>;
                        xlnx,options = <0x1>;
                        xlnx,max-intr-size = <0x20>;
                        xlnx,gpo4-size = <0x20>;
                        xlnx,tmr = <0x0>;
                        xlnx,pit1-readable = <0x1>;
                        xlnx,mask = <0xfffff000>;
                        xlnx,pit2-prescaler = <0x0>;
                        xlnx,gpi3-interrupt = <0x0>;
                        xlnx,intc-positive = <0xffff>;
                        xlnx,ip-name = "iomodule";
                        xlnx,gpo1-size = <0x3>;
                        xlnx,pit3-size = <0x20>;
                        xlnx,fit3-interrupt = <0x0>;
                        xlnx,fit1-no-clocks = <0x1848>;
                        xlnx,gpi2-size = <0x20>;
                        xlnx,pit2-readable = <0x1>;
                        xlnx,intc-irq-connection = <0x0>;
                        xlnx,uart-tx-interrupt = <0x1>;
                        xlnx,use-config-reset = <0x0>;
                        xlnx,pit2-interrupt = <0x1>;
                        xlnx,gpo4-init = <0x0>;
                        xlnx,pit3-readable = <0x1>;
                        xlnx,pit3-prescaler = <0x9>;
                        xlnx,gpi4-interrupt = <0x0>;
                        xlnx,gpo1-init = <0x0>;
                        xlnx,use-io-bus = <0x0>;
                        xlnx,use-gpo1 = <0x1>;
                        xlnx,fit4-interrupt = <0x0>;
                        xlnx,gpo3-size = <0x20>;
                        xlnx,use-gpo2 = <0x0>;
                        xlnx,uart-data-bits = <0x8>;
                        xlnx,gpio1-board-interface = "Custom";
                        xlnx,use-gpo3 = <0x0>;
                        xlnx,fit2-no-clocks = <0x1848>;
                        xlnx,gpio2-board-interface = "Custom";
                        xlnx,use-gpo4 = <0x0>;
                        xlnx,gpi4-size = <0x20>;
                        xlnx,gpio3-board-interface = "Custom";
                        xlnx,uart-rx-interrupt = <0x1>;
                        xlnx,uart-error-interrupt = <0x1>;
                        xlnx,gpio4-board-interface = "Custom";
                        xlnx,pit4-readable = <0x1>;
                        xlnx,intc-use-irq-out = <0x0>;
                        xlnx,use-board-flow;
                        xlnx,pit2-size = <0x20>;
                        xlnx,intc-intr-size = <0x10>;
                        xlnx,intc-use-ext-intr = <0x1>;
                        xlnx,name = "blp_cips_pspmc_0_psv_pmc_iomodule_0";
                        xlnx,gpi1-size = <0x20>;
                        xlnx,edk-special = "INTR_CTRL";
                        xlnx,pit3-interrupt = <0x1>;
                        xlnx,use-gpi1 = <0x0>;
                        xlnx,gpi1-interrupt = <0x0>;
                        xlnx,use-gpi2 = <0x0>;
                        xlnx,use-gpi3 = <0x0>;
                        xlnx,use-gpi4 = <0x0>;
                        xlnx,fit1-interrupt = <0x0>;
                        xlnx,pit4-prescaler = <0x0>;
                        xlnx,gpo3-init = <0x0>;
                        xlnx,edk-iptype = "PERIPHERAL";
                        xlnx,fit3-no-clocks = <0x1848>;
                        xlnx,use-uart-rx = <0x1>;
                        xlnx,instance = "iomodule_0";
                        xlnx,uart-prog-baudrate = <0x1>;
                        xlnx,use-pit1 = <0x1>;
                        xlnx,gpo2-size = <0x20>;
                        xlnx,use-pit2 = <0x1>;
                        xlnx,pit4-size = <0x20>;
                        xlnx,use-pit3 = <0x1>;
                        xlnx,use-pit4 = <0x1>;
                        xlnx,pit4-interrupt = <0x1>;
                        xlnx,gpi3-size = <0x20>;
                        xlnx,intc-async-intr = <0xffff>;
                        xlnx,avoid-primitives = <0x0>;
                        xlnx,gpi2-interrupt = <0x0>;
                        xlnx,pit1-prescaler = <0x9>;
                        xlnx,use-tmr-disable = <0x0>;
                        xlnx,use-fit1 = <0x0>;
                        xlnx,pit1-size = <0x20>;
                        xlnx,intc-num-sync-ff = <0x2>;
                        xlnx,uart-board-interface = "rs232_uart";
                        xlnx,use-fit2 = <0x0>;
                        xlnx,fit2-interrupt = <0x0>;
                        xlnx,use-fit3 = <0x0>;
                        xlnx,use-fit4 = <0x0>;
                        xlnx,uart-use-parity = <0x0>;
                        xlnx,lmb-dwidth = <0x20>;
                        xlnx,fit4-no-clocks = <0x1848>;
                        xlnx,uart-odd-parity = <0x0>;
                        xlnx,freq = <0x5f5e100>;
                        xlnx,use-uart-tx = <0x1>;
                        xlnx,pit1-interrupt = <0x1>;
                        xlnx,gpo2-init = <0x0>;
                        xlnx,io-mask = <0xfffe0000>;
                        xlnx,lmb-awidth = <0x20>;
                        phandle = <0x92>;
                };

                ipi_pmc: mailbox@ff320000 {
                        status = "okay";
                        compatible = "xlnx,zynqmp-ipi-mailbox";
                        interrupt-parent = <&imux>;
                        interrupts = <0x0 0x1b 0x4>;
                        reg = <0x0 0xff320000 0x0 0x20>;
                        xlnx,ipi-bitmask = <0x2>;
                        xlnx,ipi-id = <0x1>;
                        xlnx,ipi-buf-index = <0x1>;
                        #address-cells = <0x2>;
                        #size-cells = <0x2>;
                        ranges;
                        xlnx,cpu-name = "PMC";
                        xlnx,buffer-base = <0xff3f0200>;
                        xlnx,buffer-index = <0x1>;
                        xlnx,ip-name = "psv_ipi";
                        xlnx,ipi-target-count = <0xa>;
                        xlnx,int-id = <0x3b>;
                        xlnx,bit-position = <0x1>;
                        xlnx,name = "blp_cips_pspmc_0_psv_ipi_pmc";
                        phandle = <0x90>;

                        blp_cips_pspmc_0_psv_ipi_pmc_0: child@0 {
                                xlnx,ipi-bitmask = <0x4>;
                                xlnx,ipi-rsp-msg-buf = <0xff3f02a0>;
                                xlnx,ipi-id = <0x2>;
                                xlnx,ipi-buf-index = <0x2>;
                                xlnx,ipi-req-msg-buf = <0xff3f0280>;
                                phandle = <0xdf>;
                        };

                        blp_cips_pspmc_0_psv_ipi_pmc_1: child@1 {
                                xlnx,ipi-bitmask = <0x8>;
                                xlnx,ipi-rsp-msg-buf = <0xff3f02e0>;
                                xlnx,ipi-id = <0x3>;
                                xlnx,ipi-buf-index = <0x3>;
                                xlnx,ipi-req-msg-buf = <0xff3f02c0>;
                                phandle = <0xe0>;
                        };

                        blp_cips_pspmc_0_psv_ipi_pmc_2: child@2 {
                                xlnx,ipi-bitmask = <0x10>;
                                xlnx,ipi-rsp-msg-buf = <0xff3f0320>;
                                xlnx,ipi-id = <0x4>;
                                xlnx,ipi-buf-index = <0x4>;
                                xlnx,ipi-req-msg-buf = <0xff3f0300>;
                                phandle = <0xe1>;
                        };

                        blp_cips_pspmc_0_psv_ipi_pmc_3: child@3 {
                                xlnx,ipi-bitmask = <0x20>;
                                xlnx,ipi-rsp-msg-buf = <0xff3f0360>;
                                xlnx,ipi-id = <0x5>;
                                xlnx,ipi-buf-index = <0x5>;
                                xlnx,ipi-req-msg-buf = <0xff3f0340>;
                                phandle = <0xe2>;
                        };

                        blp_cips_pspmc_0_psv_ipi_pmc_4: child@4 {
                                xlnx,ipi-bitmask = <0x40>;
                                xlnx,ipi-rsp-msg-buf = <0xff3f03a0>;
                                xlnx,ipi-id = <0x6>;
                                xlnx,ipi-buf-index = <0x6>;
                                xlnx,ipi-req-msg-buf = <0xff3f0380>;
                                phandle = <0xe3>;
                        };

                        blp_cips_pspmc_0_psv_ipi_pmc_5: child@5 {
                                xlnx,ipi-bitmask = <0x80>;
                                xlnx,ipi-rsp-msg-buf = <0xff3f03e0>;
                                xlnx,ipi-id = <0x7>;
                                xlnx,ipi-buf-index = <0x7>;
                                xlnx,ipi-req-msg-buf = <0xff3f03c0>;
                                phandle = <0xe4>;
                        };

                        blp_cips_pspmc_0_psv_ipi_pmc_6: child@6 {
                                xlnx,ipi-bitmask = <0x200>;
                                xlnx,ipi-id = <0x9>;
                                xlnx,ipi-buf-index = <0xffff>;
                                phandle = <0xe5>;
                        };

                        blp_cips_pspmc_0_psv_ipi_pmc_7: child@7 {
                                xlnx,ipi-bitmask = <0x2>;
                                xlnx,ipi-rsp-msg-buf = <0xff3f0260>;
                                xlnx,ipi-id = <0x1>;
                                xlnx,ipi-buf-index = <0x1>;
                                xlnx,ipi-req-msg-buf = <0xff3f0240>;
                                phandle = <0xe6>;
                        };

                        blp_cips_pspmc_0_psv_ipi_pmc_8: child@8 {
                                xlnx,ipi-bitmask = <0x100>;
                                xlnx,ipi-id = <0x8>;
                                xlnx,ipi-buf-index = <0xffff>;
                                phandle = <0xe7>;
                        };

                        blp_cips_pspmc_0_psv_ipi_pmc_9: child@9 {
                                xlnx,ipi-bitmask = <0x1>;
                                xlnx,ipi-rsp-msg-buf = <0xff3f0220>;
                                xlnx,ipi-id = <0x0>;
                                xlnx,ipi-buf-index = <0x0>;
                                xlnx,ipi-req-msg-buf = <0xff3f0200>;
                                phandle = <0xe8>;
                        };
                };

                ipi_pmc_nobuf: mailbox@ff390000 {
                        status = "okay";
                        compatible = "xlnx,zynqmp-ipi-mailbox";
                        interrupt-parent = <&imux>;
                        interrupts = <0x0 0x1c 0x4>;
                        reg = <0x0 0xff390000 0x0 0x20>;
                        xlnx,ipi-bitmask = <0x100>;
                        xlnx,ipi-id = <0x8>;
                        xlnx,ipi-buf-index = <0xffff>;
                        #address-cells = <0x2>;
                        #size-cells = <0x2>;
                        ranges;
                        xlnx,cpu-name = "PMC";
                        xlnx,buffer-base = "NIL";
                        xlnx,buffer-index = "NIL";
                        xlnx,ip-name = "psv_ipi";
                        xlnx,ipi-target-count = <0xa>;
                        xlnx,int-id = <0x3c>;
                        xlnx,bit-position = <0x8>;
                        xlnx,name = "blp_cips_pspmc_0_psv_ipi_pmc_nobuf";
                        phandle = <0x91>;

                        blp_cips_pspmc_0_psv_ipi_pmc_nobuf_0: child@0 {
                                xlnx,ipi-bitmask = <0x4>;
                                xlnx,ipi-id = <0x2>;
                                xlnx,ipi-buf-index = <0x2>;
                                phandle = <0xe9>;
                        };

                        blp_cips_pspmc_0_psv_ipi_pmc_nobuf_1: child@1 {
                                xlnx,ipi-bitmask = <0x8>;
                                xlnx,ipi-id = <0x3>;
                                xlnx,ipi-buf-index = <0x3>;
                                phandle = <0xea>;
                        };

                        blp_cips_pspmc_0_psv_ipi_pmc_nobuf_2: child@2 {
                                xlnx,ipi-bitmask = <0x10>;
                                xlnx,ipi-id = <0x4>;
                                xlnx,ipi-buf-index = <0x4>;
                                phandle = <0xeb>;
                        };

                        blp_cips_pspmc_0_psv_ipi_pmc_nobuf_3: child@3 {
                                xlnx,ipi-bitmask = <0x20>;
                                xlnx,ipi-id = <0x5>;
                                xlnx,ipi-buf-index = <0x5>;
                                phandle = <0xec>;
                        };

                        blp_cips_pspmc_0_psv_ipi_pmc_nobuf_4: child@4 {
                                xlnx,ipi-bitmask = <0x40>;
                                xlnx,ipi-id = <0x6>;
                                xlnx,ipi-buf-index = <0x6>;
                                phandle = <0xed>;
                        };

                        blp_cips_pspmc_0_psv_ipi_pmc_nobuf_5: child@5 {
                                xlnx,ipi-bitmask = <0x80>;
                                xlnx,ipi-id = <0x7>;
                                xlnx,ipi-buf-index = <0x7>;
                                phandle = <0xee>;
                        };

                        blp_cips_pspmc_0_psv_ipi_pmc_nobuf_6: child@6 {
                                xlnx,ipi-bitmask = <0x200>;
                                xlnx,ipi-id = <0x9>;
                                xlnx,ipi-buf-index = <0xffff>;
                                phandle = <0xef>;
                        };

                        blp_cips_pspmc_0_psv_ipi_pmc_nobuf_7: child@7 {
                                xlnx,ipi-bitmask = <0x2>;
                                xlnx,ipi-id = <0x1>;
                                xlnx,ipi-buf-index = <0x1>;
                                phandle = <0xf0>;
                        };

                        blp_cips_pspmc_0_psv_ipi_pmc_nobuf_8: child@8 {
                                xlnx,ipi-bitmask = <0x100>;
                                xlnx,ipi-id = <0x8>;
                                xlnx,ipi-buf-index = <0xffff>;
                                phandle = <0xf1>;
                        };

                        blp_cips_pspmc_0_psv_ipi_pmc_nobuf_9: child@9 {
                                xlnx,ipi-bitmask = <0x1>;
                                xlnx,ipi-id = <0x0>;
                                xlnx,ipi-buf-index = <0x0>;
                                phandle = <0xf2>;
                        };
                };

                blp_cips_pspmc_0_psv_r5_0_atcm: blp_cips_pspmc_0_psv_r5_0_atcm@0 {
                        xlnx,power-domain = <0x1831800b>;
                        compatible = "xlnx,psv-r5-tcm-1.0";
                        status = "okay";
                        xlnx,ip-name = "psv_r5_tcm";
                        xlnx,bank-size = <0x10000>;
                        reg = <0x0 0x0 0x0 0x10000>;
                        xlnx,name = "blp_cips_pspmc_0_psv_r5_0_atcm";
                        phandle = <0x9c>;
                };

                blp_cips_pspmc_0_psv_r5_0_atcm_lockstep: blp_cips_pspmc_0_psv_r5_0_atcm_lockstep@ffe10000 {
                        compatible = "xlnx,psv-r5-0-atcm-lockstep-1.0", "mmio-sram";
                        status = "okay";
                        power-domains = <&versal_firmware 0x1831800b>;
                        xlnx,ip-name = "psv_r5_0_atcm_lockstep";
                        xlnx,is-hierarchy;
                        reg = <0x0 0xffe10000 0x0 0x10000>;
                        xlnx,name = "blp_cips_pspmc_0_psv_r5_0_atcm_lockstep";
                        phandle = <0x14c>;
                };

                blp_cips_pspmc_0_psv_r5_0_btcm: blp_cips_pspmc_0_psv_r5_0_btcm@20000 {
                        xlnx,power-domain = <0x1831800c>;
                        compatible = "xlnx,psv-r5-tcm-1.0";
                        status = "okay";
                        xlnx,ip-name = "psv_r5_tcm";
                        xlnx,bank-size = <0x10000>;
                        reg = <0x0 0x20000 0x0 0x10000>;
                        xlnx,name = "blp_cips_pspmc_0_psv_r5_0_btcm";
                        phandle = <0x9e>;
                };

                blp_cips_pspmc_0_psv_r5_0_btcm_lockstep: blp_cips_pspmc_0_psv_r5_0_btcm_lockstep@ffe30000 {
                        compatible = "xlnx,psv-r5-0-btcm-lockstep-1.0", "mmio-sram";
                        status = "okay";
                        power-domains = <&versal_firmware 0x1831800c>;
                        xlnx,ip-name = "psv_r5_0_btcm_lockstep";
                        xlnx,is-hierarchy;
                        reg = <0x0 0xffe30000 0x0 0x10000>;
                        xlnx,name = "blp_cips_pspmc_0_psv_r5_0_btcm_lockstep";
                        phandle = <0x14d>;
                };

                blp_cips_pspmc_0_psv_r5_1_atcm: blp_cips_pspmc_0_psv_r5_1_atcm@0 {
                        xlnx,power-domain = <0x1831800d>;
                        compatible = "xlnx,psv-r5-tcm-1.0";
                        status = "okay";
                        xlnx,ip-name = "psv_r5_tcm";
                        xlnx,bank-size = <0x10000>;
                        reg = <0x0 0x0 0x0 0x10000>;
                        xlnx,name = "blp_cips_pspmc_0_psv_r5_1_atcm";
                        phandle = <0xa6>;
                };

                blp_cips_pspmc_0_psv_r5_1_btcm: blp_cips_pspmc_0_psv_r5_1_btcm@20000 {
                        xlnx,power-domain = <0x1831800e>;
                        compatible = "xlnx,psv-r5-tcm-1.0";
                        status = "okay";
                        xlnx,ip-name = "psv_r5_tcm";
                        xlnx,bank-size = <0x10000>;
                        reg = <0x0 0x20000 0x0 0x10000>;
                        xlnx,name = "blp_cips_pspmc_0_psv_r5_1_btcm";
                        phandle = <0xa7>;
                };

                blp_cips_pspmc_0_psv_r5_tcm_ram_0: blp_cips_pspmc_0_psv_r5_tcm_ram_0@0 {
                        compatible = "xlnx,psv-r5-tcm-1.0";
                        status = "okay";
                        xlnx,ip-name = "psv_r5_tcm";
                        reg = <0x0 0x0 0x0 0x40000>;
                        xlnx,name = "blp_cips_pspmc_0_psv_r5_tcm_ram_0";
                        phandle = <0x9d>;
                };
        };

        psv_r5_0_atcm_global: psv_r5_0_atcm_global@ffe00000 {
                compatible = "xlnx,psv-tcm-global-1.0", "mmio-sram";
                power-domains = <&versal_firmware 0x1831800b>;
                reg = <0x0 0xffe00000 0x0 0x10000>;
                status = "okay";
                xlnx,ip-name = "psv_tcm_global";
                xlnx,is-hierarchy;
                xlnx,name = "blp_cips_pspmc_0_psv_r5_0_atcm_global";
                phandle = <0x84>;
        };

        psv_r5_0_btcm_global: psv_r5_0_btcm_global@ffe20000 {
                compatible = "xlnx,psv-tcm-global-1.0", "mmio-sram";
                power-domains = <&versal_firmware 0x1831800c>;
                reg = <0x0 0xffe20000 0x0 0x10000>;
                status = "okay";
                xlnx,ip-name = "psv_tcm_global";
                xlnx,is-hierarchy;
                xlnx,name = "blp_cips_pspmc_0_psv_r5_0_btcm_global";
                phandle = <0x161>;
        };

        psv_r5_1_atcm_global: psv_r5_1_atcm_global@ffe90000 {
                compatible = "xlnx,psv-tcm-global-1.0", "mmio-sram";
                power-domains = <&versal_firmware 0x1831800d>;
                reg = <0x0 0xffe90000 0x0 0x10000>;
                status = "okay";
                xlnx,ip-name = "psv_tcm_global";
                xlnx,name = "blp_cips_pspmc_0_psv_r5_1_atcm_global";
                phandle = <0x85>;
        };

        psv_r5_1_btcm_global: psv_r5_1_btcm_global@ffeb0000 {
                compatible = "xlnx,psv-tcm-global-1.0", "mmio-sram";
                power-domains = <&versal_firmware 0x1831800e>;
                reg = <0x0 0xffeb0000 0x0 0x10000>;
                status = "okay";
                xlnx,ip-name = "psv_tcm_global";
                xlnx,name = "blp_cips_pspmc_0_psv_r5_1_btcm_global";
                phandle = <0x86>;
        };

        amba_xppu: indirect-bus@1 {
                compatible = "indirect-bus";
                #address-cells = <0x2>;
                #size-cells = <0x2>;
                phandle = <0x162>;
        };

        amba_xmpu: indirect-bus@2 {
                compatible = "indirect-bus";
                #address-cells = <0x2>;
                #size-cells = <0x2>;
                phandle = <0x163>;
        };

        pl_alt_ref: pl-alt-ref {
                bootph-all;
                compatible = "fixed-clock";
                #clock-cells = <0x0>;
                clock-frequency = <0x1fca055>;
                clock-output-names = "pl_alt_ref_clk";
                phandle = <0xb1>;
        };

        ref: ref {
                bootph-all;
                compatible = "fixed-clock";
                #clock-cells = <0x0>;
                clock-frequency = <0x1fca034>;
                clock-output-names = "ref_clk";
                phandle = <0xb0>;
        };

        can0_clk: can0-clk {
                #clock-cells = <0x0>;
                compatible = "fixed-factor-clock";
                clocks = <&versal_clk 0x60>;
                clock-div = <0x2>;
                clock-mult = <0x1>;
                clock-output-names = "can0_clk";
                phandle = <0xab>;
        };

        can1_clk: can1-clk {
                #clock-cells = <0x0>;
                compatible = "fixed-factor-clock";
                clocks = <&versal_clk 0x61>;
                clock-div = <0x2>;
                clock-mult = <0x1>;
                clock-output-names = "can1_clk";
                phandle = <0xac>;
        };

        firmware {

                versal_firmware: versal-firmware {
                        compatible = "xlnx,versal-firmware";
                        interrupt-parent = <&imux>;
                        bootph-all;
                        method = "smc";
                        #power-domain-cells = <0x1>;
                        phandle = <0x8e>;

                        versal_clk: clock-controller {
                                bootph-all;
                                #clock-cells = <0x1>;
                                compatible = "xlnx,versal-clk";
                                clocks = <&ref>,
                                 <&pl_alt_ref>;
                                clock-names = "ref", "pl_alt_ref";
                                phandle = <0x8f>;
                        };

                        zynqmp_power: power-management {
                                compatible = "xlnx,zynqmp-power";
                                phandle = <0x168>;
                        };

                        versal_reset: reset-controller {
                                compatible = "xlnx,versal-reset";
                                #reset-cells = <0x1>;
                                phandle = <0xad>;
                        };

                        pinctrl0: pinctrl {
                                compatible = "xlnx,versal-pinctrl";
                                phandle = <0x169>;
                        };

                        versal_sec_cfg: versal-sec-cfg {
                                compatible = "xlnx,versal-sec-cfg";
                                phandle = <0x16a>;

                                nvmem-layout {
                                        compatible = "fixed-layout";
                                        #address-cells = <0x1>;
                                        #size-cells = <0x1>;

                                        bbram_zeroize: bbram-zeroize@4 {
                                                reg = <0x4 0x4>;
                                                phandle = <0x16b>;
                                        };

                                        bbram_key: bbram-key@10 {
                                                reg = <0x10 0x20>;
                                                phandle = <0x16c>;
                                        };

                                        bbram_usr: bbram-usr@30 {
                                                reg = <0x30 0x4>;
                                                phandle = <0x16d>;
                                        };

                                        bbram_lock: bbram-lock@48 {
                                                reg = <0x48 0x4>;
                                                phandle = <0x16e>;
                                        };

                                        user_key0: user-key@110 {
                                                reg = <0x110 0x20>;
                                                phandle = <0x16f>;
                                        };

                                        user_key1: user-key@130 {
                                                reg = <0x130 0x20>;
                                                phandle = <0x170>;
                                        };

                                        user_key2: user-key@150 {
                                                reg = <0x150 0x20>;
                                                phandle = <0x171>;
                                        };

                                        user_key3: user-key@170 {
                                                reg = <0x170 0x20>;
                                                phandle = <0x172>;
                                        };

                                        user_key4: user-key@190 {
                                                reg = <0x190 0x20>;
                                                phandle = <0x173>;
                                        };

                                        user_key5: user-key@1b0 {
                                                reg = <0x1b0 0x20>;
                                                phandle = <0x174>;
                                        };

                                        user_key6: user-key@1d0 {
                                                reg = <0x1d0 0x20>;
                                                phandle = <0x175>;
                                        };

                                        user_key7: user-key@1f0 {
                                                reg = <0x1f0 0x20>;
                                                phandle = <0x176>;
                                        };
                                };
                        };
                };
        };

        amba_pl: amba_pl {
                ranges;
                compatible = "simple-bus";
                #address-cells = <0x2>;
                #size-cells = <0x2>;
                firmware-name = "ve2302_pcie_qdma_base.pdi";
                phandle = <0x177>;

                fpga_PR: fpga-PR {
                        ranges;
                        compatible = "fpga-region";
                        #address-cells = <0x2>;
                        #size-cells = <0x2>;
                        phandle = <0x178>;
                };

                misc_clk_0: misc_clk_0 {
                        compatible = "fixed-clock";
                        clock-frequency = <0x7735940>;
                        #clock-cells = <0x0>;
                        phandle = <0xb2>;
                };
        };

        chosen {
                stdout-path = "serial0:115200";
                bootargs = "earlycon clk_ignore_unused";
        };

        aliases {
                serial4 = "/amba_pl/serial@20102020000";
                serial0 = "/axi/serial@ff000000";
                serial5 = "/amba_pl/serial@80021000";
                serial1 = "/axi/serial@ff010000";
                serial6 = "/axi/coresight@f0800000";
                serial2 = "/amba_pl/serial@402020000";
                serial3 = "/amba_pl/serial@20102021000";
                i2c0 = "/axi/i2c@ff020000";
        };

        onewire {
                compatible = "w1-gpio";
                gpios = <&gpio0 0x4 0x0>;
        };

        __symbols__ {
                cpus_microblaze_0 = "/cpus_microblaze@0";
                psv_pmc_0 = "/cpus_microblaze@0/cpu@0";
                cpu_opp_table = "/opp-table-cpu";
                fpga = "/fpga-region";
                psci = "/psci";
                timer = "/timer";
                versal_fpga = "/versal-fpga";
                sensor0 = "/versal-thermal-sensor";
                versal_thermal = "/thermal-zones/versal-thermal";
                temp_alert = "/thermal-zones/versal-thermal/trips/temp-alert";
                ot_crit = "/thermal-zones/versal-thermal/trips/ot-crit";
                amba_apu = "/apu-bus";
                amba_rpu = "/rpu-bus";
                amba = "/axi";
                imux = "/axi/interrupt-multiplex";
                lpd_dma_chan0 = "/axi/dma-controller@ffa80000";
                lpd_dma_chan1 = "/axi/dma-controller@ffa90000";
                lpd_dma_chan2 = "/axi/dma-controller@ffaa0000";
                lpd_dma_chan3 = "/axi/dma-controller@ffab0000";
                lpd_dma_chan4 = "/axi/dma-controller@ffac0000";
                lpd_dma_chan5 = "/axi/dma-controller@ffad0000";
                lpd_dma_chan6 = "/axi/dma-controller@ffae0000";
                lpd_dma_chan7 = "/axi/dma-controller@ffaf0000";
                gpio0 = "/axi/gpio@ff0b0000";
                gpio1 = "/axi/gpio@f1020000";
                i2c2 = "/axi/i2c@f1000000";
                ocm = "/axi/memory-controller@ff960000";
                serial0 = "/axi/serial@ff000000";
                serial1 = "/axi/serial@ff010000";
                ospi = "/axi/spi@f1010000";
                sysmon0 = "/axi/sysmon@f1270000";
                ttc0 = "/axi/timer@ff0e0000";
                ttc1 = "/axi/timer@ff0f0000";
                ttc2 = "/axi/timer@ff100000";
                ttc3 = "/axi/timer@ff110000";
                dma0 = "/axi/pmcdma@f11c0000";
                dma1 = "/axi/pmcdma@f11d0000";
                pmc_trng = "/axi/pmc_trng@f1230000";
                pmc_cfi_cframe_0 = "/axi/cframe@f12d0000";
                pmc_cfu_apb_0 = "/axi/cfu_apb@f12b0000";
                pmc_ppu1_mdm_0 = "/axi/ppu1_mdm@f0310000";
                iomodule0 = "/axi/iomodule@f0280000";
                ipi_pmc = "/axi/mailbox@ff320000";
                blp_cips_pspmc_0_psv_ipi_pmc_0 = "/axi/mailbox@ff320000/child@0";
                blp_cips_pspmc_0_psv_ipi_pmc_1 = "/axi/mailbox@ff320000/child@1";
                blp_cips_pspmc_0_psv_ipi_pmc_2 = "/axi/mailbox@ff320000/child@2";
                blp_cips_pspmc_0_psv_ipi_pmc_3 = "/axi/mailbox@ff320000/child@3";
                blp_cips_pspmc_0_psv_ipi_pmc_4 = "/axi/mailbox@ff320000/child@4";
                blp_cips_pspmc_0_psv_ipi_pmc_5 = "/axi/mailbox@ff320000/child@5";
                blp_cips_pspmc_0_psv_ipi_pmc_6 = "/axi/mailbox@ff320000/child@6";
                blp_cips_pspmc_0_psv_ipi_pmc_7 = "/axi/mailbox@ff320000/child@7";
                blp_cips_pspmc_0_psv_ipi_pmc_8 = "/axi/mailbox@ff320000/child@8";
                blp_cips_pspmc_0_psv_ipi_pmc_9 = "/axi/mailbox@ff320000/child@9";
                ipi_pmc_nobuf = "/axi/mailbox@ff390000";
                blp_cips_pspmc_0_psv_ipi_pmc_nobuf_0 = "/axi/mailbox@ff390000/child@0";
                blp_cips_pspmc_0_psv_ipi_pmc_nobuf_1 = "/axi/mailbox@ff390000/child@1";
                blp_cips_pspmc_0_psv_ipi_pmc_nobuf_2 = "/axi/mailbox@ff390000/child@2";
                blp_cips_pspmc_0_psv_ipi_pmc_nobuf_3 = "/axi/mailbox@ff390000/child@3";
                blp_cips_pspmc_0_psv_ipi_pmc_nobuf_4 = "/axi/mailbox@ff390000/child@4";
                blp_cips_pspmc_0_psv_ipi_pmc_nobuf_5 = "/axi/mailbox@ff390000/child@5";
                blp_cips_pspmc_0_psv_ipi_pmc_nobuf_6 = "/axi/mailbox@ff390000/child@6";
                blp_cips_pspmc_0_psv_ipi_pmc_nobuf_7 = "/axi/mailbox@ff390000/child@7";
                blp_cips_pspmc_0_psv_ipi_pmc_nobuf_8 = "/axi/mailbox@ff390000/child@8";
                blp_cips_pspmc_0_psv_ipi_pmc_nobuf_9 = "/axi/mailbox@ff390000/child@9";
                blp_cips_pspmc_0_psv_r5_0_atcm = "/axi/blp_cips_pspmc_0_psv_r5_0_atcm@0";
                blp_cips_pspmc_0_psv_r5_0_atcm_lockstep = "/axi/blp_cips_pspmc_0_psv_r5_0_atcm_lockstep@ffe10000";
                blp_cips_pspmc_0_psv_r5_0_btcm = "/axi/blp_cips_pspmc_0_psv_r5_0_btcm@20000";
                blp_cips_pspmc_0_psv_r5_0_btcm_lockstep = "/axi/blp_cips_pspmc_0_psv_r5_0_btcm_lockstep@ffe30000";
                blp_cips_pspmc_0_psv_r5_1_atcm = "/axi/blp_cips_pspmc_0_psv_r5_1_atcm@0";
                blp_cips_pspmc_0_psv_r5_1_btcm = "/axi/blp_cips_pspmc_0_psv_r5_1_btcm@20000";
                blp_cips_pspmc_0_psv_r5_tcm_ram_0 = "/axi/blp_cips_pspmc_0_psv_r5_tcm_ram_0@0";
                psv_r5_0_atcm_global = "/psv_r5_0_atcm_global@ffe00000";
                psv_r5_0_btcm_global = "/psv_r5_0_btcm_global@ffe20000";
                psv_r5_1_atcm_global = "/psv_r5_1_atcm_global@ffe90000";
                psv_r5_1_btcm_global = "/psv_r5_1_btcm_global@ffeb0000";
                amba_xppu = "/indirect-bus@1";
                amba_xmpu = "/indirect-bus@2";
                pl_alt_ref = "/pl-alt-ref";
                ref = "/ref";
                can0_clk = "/can0-clk";
                can1_clk = "/can1-clk";
                versal_firmware = "/firmware/versal-firmware";
                versal_clk = "/firmware/versal-firmware/clock-controller";
                zynqmp_power = "/firmware/versal-firmware/power-management";
                versal_reset = "/firmware/versal-firmware/reset-controller";
                pinctrl0 = "/firmware/versal-firmware/pinctrl";
                versal_sec_cfg = "/firmware/versal-firmware/versal-sec-cfg";
                bbram_zeroize = "/firmware/versal-firmware/versal-sec-cfg/nvmem-layout/bbram-zeroize@4";
                bbram_key = "/firmware/versal-firmware/versal-sec-cfg/nvmem-layout/bbram-key@10";
                bbram_usr = "/firmware/versal-firmware/versal-sec-cfg/nvmem-layout/bbram-usr@30";
                bbram_lock = "/firmware/versal-firmware/versal-sec-cfg/nvmem-layout/bbram-lock@48";
                user_key0 = "/firmware/versal-firmware/versal-sec-cfg/nvmem-layout/user-key@110";
                user_key1 = "/firmware/versal-firmware/versal-sec-cfg/nvmem-layout/user-key@130";
                user_key2 = "/firmware/versal-firmware/versal-sec-cfg/nvmem-layout/user-key@150";
                user_key3 = "/firmware/versal-firmware/versal-sec-cfg/nvmem-layout/user-key@170";
                user_key4 = "/firmware/versal-firmware/versal-sec-cfg/nvmem-layout/user-key@190";
                user_key5 = "/firmware/versal-firmware/versal-sec-cfg/nvmem-layout/user-key@1b0";
                user_key6 = "/firmware/versal-firmware/versal-sec-cfg/nvmem-layout/user-key@1d0";
                user_key7 = "/firmware/versal-firmware/versal-sec-cfg/nvmem-layout/user-key@1f0";
                amba_pl = "/amba_pl";
                fpga_PR = "/amba_pl/fpga-PR";
                misc_clk_0 = "/amba_pl/misc_clk_0";
        };
};
